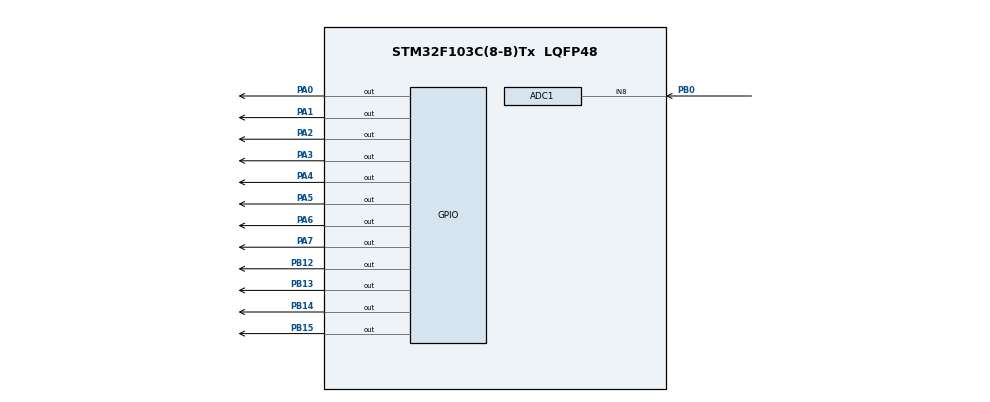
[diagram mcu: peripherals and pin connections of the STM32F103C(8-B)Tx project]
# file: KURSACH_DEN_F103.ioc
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ADC1.Channel-1\#ChannelRegularConversion=ADC_CHANNEL_8
ADC1.ContinuousConvMode=ENABLE
ADC1.NbrOfConversionFlag=1
ADC1.Rank-1\#ChannelRegularConversion=1
ADC1.SamplingTime-1\#ChannelRegularConversion=ADC_SAMPLETIME_1CYCLE_5
ADC1.master=1
Mcu.Family=STM32F1
Mcu.Name=STM32F103C(8-B)Tx
Mcu.Package=LQFP48
NVIC.ADC1_2_IRQn=true\:0\:0\:false\:false\:true\:true\:true
NVIC.PriorityGroup=NVIC_PRIORITYGROUP_4
NVIC.TIM1_UP_IRQn=true\:0\:0\:false\:false\:true\:true\:true
NVIC.TIM2_IRQn=true\:0\:0\:false\:false\:true\:true\:true
PA0-WKUP.GPIO_Speed=GPIO_SPEED_FREQ_MEDIUM
PA0-WKUP.Signal=GPIO_Output
PA1.GPIO_Speed=GPIO_SPEED_FREQ_MEDIUM
PA1.Signal=GPIO_Output
PA13.Mode=Serial_Wire
PA13.Signal=SYS_JTMS-SWDIO
PA14.Mode=Serial_Wire
PA14.Signal=SYS_JTCK-SWCLK
PA2.GPIO_Speed=GPIO_SPEED_FREQ_MEDIUM
PA2.Signal=GPIO_Output
PA3.GPIO_Speed=GPIO_SPEED_FREQ_MEDIUM
PA3.Signal=GPIO_Output
PA4.GPIO_Speed=GPIO_SPEED_FREQ_MEDIUM
PA4.Signal=GPIO_Output
PA5.GPIO_Speed=GPIO_SPEED_FREQ_MEDIUM
PA5.Signal=GPIO_Output
PA6.GPIO_Speed=GPIO_SPEED_FREQ_MEDIUM
PA6.Signal=GPIO_Output
PA7.GPIO_Speed=GPIO_SPEED_FREQ_MEDIUM
PA7.Signal=GPIO_Output
PB0.Signal=ADCx_IN8
PB12.GPIO_Speed=GPIO_SPEED_FREQ_MEDIUM
PB12.PinState=GPIO_PIN_SET
PB12.Signal=GPIO_Output
PB13.GPIO_Speed=GPIO_SPEED_FREQ_MEDIUM
PB13.PinState=GPIO_PIN_SET
PB13.Signal=GPIO_Output
PB14.GPIO_Speed=GPIO_SPEED_FREQ_MEDIUM
PB14.PinState=GPIO_PIN_SET
PB14.Signal=GPIO_Output
PB15.GPIO_Speed=GPIO_SPEED_FREQ_MEDIUM
PB15.PinState=GPIO_PIN_SET
PB15.Signal=GPIO_Output
PD0-OSC_IN.Mode=HSE-External-Oscillator
PD0-OSC_IN.Signal=RCC_OSC_IN
PD1-OSC_OUT.Mode=HSE-External-Oscillator
PD1-OSC_OUT.Signal=RCC_OSC_OUT
ProjectManager.HeapSize=0x200
ProjectManager.StackSize=0x400
ProjectManager.TargetToolchain=EWARM V8
RCC.APB1Freq_Value=8000000
RCC.APB2Freq_Value=8000000
SH.ADCx_IN8.0=ADC1_IN8,IN8
TIM1.Period=200
TIM1.Prescaler=199
TIM2.Period=100
TIM2.Prescaler=7999
VP_TIM1_VS_ClockSourceINT.Mode=Internal
VP_TIM1_VS_ClockSourceITR.Mode=TriggerSource_ITR0
VP_TIM2_VS_ClockSourceINT.Mode=Internal
VP_TIM2_VS_ClockSourceITR.Mode=TriggerSource_ITR0
board=custom

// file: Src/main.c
/* USER CODE BEGIN Header */
/**
  ******************************************************************************
  * @file           : main.c
  * @brief          : Main program body
  ******************************************************************************
  * @attention
  *
  * <h2><center>&copy; Copyright (c) 2019 STMicroelectronics.
  * All rights reserved.</center></h2>
  *
  * This software component is licensed by ST under BSD 3-Clause license,
  * the "License"; You may not use this file except in compliance with the
  * License. You may obtain a copy of the License at:
  *                        opensource.org/licenses/BSD-3-Clause
  *
  ******************************************************************************
  */
/* USER CODE END Header */

#include "main.h"

/* USER CODE BEGIN Includes */
#include "global.h"
/* USER CODE END Includes */

TIM_HandleTypeDef htim2;

/* USER CODE BEGIN PV */
int i=1234;
/* USER CODE END PV */

void SystemClock_Config(void);
static void MX_GPIO_Init(void);
static void MX_ADC1_Init(void);
static void MX_TIM1_Init(void);
static void MX_TIM2_Init(void);

int main(void)
{

  /* MCU Configuration--------------------------------------------------------*/

  /* Reset of all peripherals, Initializes the Flash interface and the Systick. */
  HAL_Init();

  /* Configure the system clock */
  SystemClock_Config();

  /* USER CODE BEGIN SysInit */
  LL_ADC_StartCalibration(ADC1);//?????? ?????????? ???1
while (LL_ADC_IsCalibrationOnGoing(ADC1) != RESET);//??????? ?????????? ?????????? ???1
//ADC32 = LL_ADC_REF_ReadConversionData12(ADC1);//??? ??????
  /* USER CODE END SysInit */

  /* Initialize all configured peripherals */
  MX_GPIO_Init();
  MX_ADC1_Init();
  MX_TIM1_Init();
  MX_TIM2_Init();
  /* USER CODE BEGIN 2 */

LL_ADC_EnableIT_EOS(ADC1);//?????????? ?????????? ?? ?????????? ?????????????? ? ???
LL_ADC_Enable(ADC1);//????????? ???

LL_TIM_EnableIT_UPDATE(TIM1);
LL_TIM_EnableCounter(TIM1);
LL_TIM_EnableIT_UPDATE(TIM2);
LL_TIM_EnableCounter(TIM2);

  /* USER CODE END 2 */

  /* Infinite loop */
  while (1)
  {

    /* USER CODE BEGIN 3 */

 D1=(RESULT/DELITEL)/1000%10;
 D2=(RESULT/DELITEL)/100%10;
 D3=(RESULT/DELITEL)/10%10;
 D4=(RESULT/DELITEL)/1%10;

  }
  /* USER CODE END 3 */
}

void SystemClock_Config(void)
{
  LL_FLASH_SetLatency(LL_FLASH_LATENCY_0);

  if(LL_FLASH_GetLatency() != LL_FLASH_LATENCY_0)
  {
    Error_Handler();
  }
  LL_RCC_HSI_SetCalibTrimming(16);
  LL_RCC_HSI_Enable();

   /* Wait till HSI is ready */
  while(LL_RCC_HSI_IsReady() != 1)
  {

  }
  LL_RCC_SetAHBPrescaler(LL_RCC_SYSCLK_DIV_1);
  LL_RCC_SetAPB1Prescaler(LL_RCC_APB1_DIV_1);
  LL_RCC_SetAPB2Prescaler(LL_RCC_APB2_DIV_1);
  LL_RCC_SetSysClkSource(LL_RCC_SYS_CLKSOURCE_HSI);

   /* Wait till System clock is ready */
  while(LL_RCC_GetSysClkSource() != LL_RCC_SYS_CLKSOURCE_STATUS_HSI)
  {

  }
  LL_Init1msTick(8000000);
  LL_SYSTICK_SetClkSource(LL_SYSTICK_CLKSOURCE_HCLK);
  LL_SetSystemCoreClock(8000000);
  LL_RCC_SetADCClockSource(LL_RCC_ADC_CLKSRC_PCLK2_DIV_2);
}

static void MX_ADC1_Init(void)
{

  LL_ADC_InitTypeDef ADC_InitStruct = {0};
  LL_ADC_CommonInitTypeDef ADC_CommonInitStruct = {0};
  LL_ADC_REG_InitTypeDef ADC_REG_InitStruct = {0};

  LL_GPIO_InitTypeDef GPIO_InitStruct = {0};

  /* Peripheral clock enable */
  LL_APB2_GRP1_EnableClock(LL_APB2_GRP1_PERIPH_ADC1);

  LL_APB2_GRP1_EnableClock(LL_APB2_GRP1_PERIPH_GPIOB);
  /**ADC1 GPIO Configuration
  PB0   ------> ADC1_IN8
  */
  GPIO_InitStruct.Pin = LL_GPIO_PIN_0;
  GPIO_InitStruct.Mode = LL_GPIO_MODE_ANALOG;
  LL_GPIO_Init(GPIOB, &GPIO_InitStruct);

  /* ADC1 interrupt Init */
  NVIC_SetPriority(ADC1_2_IRQn, NVIC_EncodePriority(NVIC_GetPriorityGrouping(),0, 0));
  NVIC_EnableIRQ(ADC1_2_IRQn);

  /** Common config
  */
  ADC_InitStruct.DataAlignment = LL_ADC_DATA_ALIGN_RIGHT;
  ADC_InitStruct.SequencersScanMode = LL_ADC_SEQ_SCAN_DISABLE;
  LL_ADC_Init(ADC1, &ADC_InitStruct);
  ADC_CommonInitStruct.Multimode = LL_ADC_MULTI_INDEPENDENT;
  LL_ADC_CommonInit(__LL_ADC_COMMON_INSTANCE(ADC1), &ADC_CommonInitStruct);
  ADC_REG_InitStruct.TriggerSource = LL_ADC_REG_TRIG_SOFTWARE;
  ADC_REG_InitStruct.SequencerLength = 1;
  ADC_REG_InitStruct.SequencerDiscont = LL_ADC_REG_SEQ_DISCONT_DISABLE;
  ADC_REG_InitStruct.ContinuousMode = LL_ADC_REG_CONV_CONTINUOUS;
  ADC_REG_InitStruct.DMATransfer = LL_ADC_REG_DMA_TRANSFER_NONE;
  LL_ADC_REG_Init(ADC1, &ADC_REG_InitStruct);
  /** Configure Regular Channel
  */
  LL_ADC_REG_SetSequencerRanks(ADC1, LL_ADC_REG_RANK_1, LL_ADC_CHANNEL_8);
  LL_ADC_SetChannelSamplingTime(ADC1, LL_ADC_CHANNEL_8, LL_ADC_SAMPLINGTIME_1CYCLE_5);

}

static void MX_TIM1_Init(void)
{

  LL_TIM_InitTypeDef TIM_InitStruct = {0};

  /* Peripheral clock enable */
  LL_APB2_GRP1_EnableClock(LL_APB2_GRP1_PERIPH_TIM1);

  /* TIM1 interrupt Init */
  NVIC_SetPriority(TIM1_UP_IRQn, NVIC_EncodePriority(NVIC_GetPriorityGrouping(),0, 0));
  NVIC_EnableIRQ(TIM1_UP_IRQn);

  TIM_InitStruct.Prescaler = 199;
  TIM_InitStruct.CounterMode = LL_TIM_COUNTERMODE_UP;
  TIM_InitStruct.Autoreload = 200;
  TIM_InitStruct.ClockDivision = LL_TIM_CLOCKDIVISION_DIV1;
  TIM_InitStruct.RepetitionCounter = 0;
  LL_TIM_Init(TIM1, &TIM_InitStruct);
  LL_TIM_DisableARRPreload(TIM1);
  LL_TIM_SetClockSource(TIM1, LL_TIM_CLOCKSOURCE_INTERNAL);
  LL_TIM_SetTriggerInput(TIM1, LL_TIM_TS_ITR0);
  LL_TIM_SetSlaveMode(TIM1, LL_TIM_SLAVEMODE_DISABLED);
  LL_TIM_DisableIT_TRIG(TIM1);
  LL_TIM_DisableDMAReq_TRIG(TIM1);
  LL_TIM_SetTriggerOutput(TIM1, LL_TIM_TRGO_RESET);
  LL_TIM_DisableMasterSlaveMode(TIM1);

}

static void MX_TIM2_Init(void)
{

  TIM_ClockConfigTypeDef sClockSourceConfig = {0};
  TIM_SlaveConfigTypeDef sSlaveConfig = {0};
  TIM_MasterConfigTypeDef sMasterConfig = {0};

  htim2.Instance = TIM2;
  htim2.Init.Prescaler = 7999;
  htim2.Init.CounterMode = TIM_COUNTERMODE_UP;
  htim2.Init.Period = 100;
  htim2.Init.ClockDivision = TIM_CLOCKDIVISION_DIV1;
  htim2.Init.AutoReloadPreload = TIM_AUTORELOAD_PRELOAD_DISABLE;
  if (HAL_TIM_Base_Init(&htim2) != HAL_OK)
  {
    Error_Handler();
  }
  sClockSourceConfig.ClockSource = TIM_CLOCKSOURCE_INTERNAL;
  if (HAL_TIM_ConfigClockSource(&htim2, &sClockSourceConfig) != HAL_OK)
  {
    Error_Handler();
  }
  sSlaveConfig.SlaveMode = TIM_SLAVEMODE_DISABLE;
  sSlaveConfig.InputTrigger = TIM_TS_ITR0;
  if (HAL_TIM_SlaveConfigSynchronization(&htim2, &sSlaveConfig) != HAL_OK)
  {
    Error_Handler();
  }
  sMasterConfig.MasterOutputTrigger = TIM_TRGO_RESET;
  sMasterConfig.MasterSlaveMode = TIM_MASTERSLAVEMODE_DISABLE;
  if (HAL_TIMEx_MasterConfigSynchronization(&htim2, &sMasterConfig) != HAL_OK)
  {
    Error_Handler();
  }

}

static void MX_GPIO_Init(void)
{
  GPIO_InitTypeDef GPIO_InitStruct = {0};

  /* GPIO Ports Clock Enable */
  __HAL_RCC_GPIOD_CLK_ENABLE();
  __HAL_RCC_GPIOA_CLK_ENABLE();
  __HAL_RCC_GPIOB_CLK_ENABLE();

  /*Configure GPIO pin Output Level */
  HAL_GPIO_WritePin(GPIOA, GPIO_PIN_0|GPIO_PIN_1|GPIO_PIN_2|GPIO_PIN_3
                          |GPIO_PIN_4|GPIO_PIN_5|GPIO_PIN_6|GPIO_PIN_7, GPIO_PIN_RESET);

  /*Configure GPIO pin Output Level */
  HAL_GPIO_WritePin(GPIOB, GPIO_PIN_12|GPIO_PIN_13|GPIO_PIN_14|GPIO_PIN_15, GPIO_PIN_SET);

  /*Configure GPIO pins : PA0 PA1 PA2 PA3
                           PA4 PA5 PA6 PA7 */
  GPIO_InitStruct.Pin = GPIO_PIN_0|GPIO_PIN_1|GPIO_PIN_2|GPIO_PIN_3
                          |GPIO_PIN_4|GPIO_PIN_5|GPIO_PIN_6|GPIO_PIN_7;
  GPIO_InitStruct.Mode = GPIO_MODE_OUTPUT_PP;
  GPIO_InitStruct.Pull = GPIO_NOPULL;
  GPIO_InitStruct.Speed = GPIO_SPEED_FREQ_MEDIUM;
  HAL_GPIO_Init(GPIOA, &GPIO_InitStruct);

  /*Configure GPIO pins : PB12 PB13 PB14 PB15 */
  GPIO_InitStruct.Pin = GPIO_PIN_12|GPIO_PIN_13|GPIO_PIN_14|GPIO_PIN_15;
  GPIO_InitStruct.Mode = GPIO_MODE_OUTPUT_PP;
  GPIO_InitStruct.Pull = GPIO_NOPULL;
  GPIO_InitStruct.Speed = GPIO_SPEED_FREQ_MEDIUM;
  HAL_GPIO_Init(GPIOB, &GPIO_InitStruct);

}

void Error_Handler(void)
{
}

/************************ (C) COPYRIGHT STMicroelectronics *****END OF FILE****/
